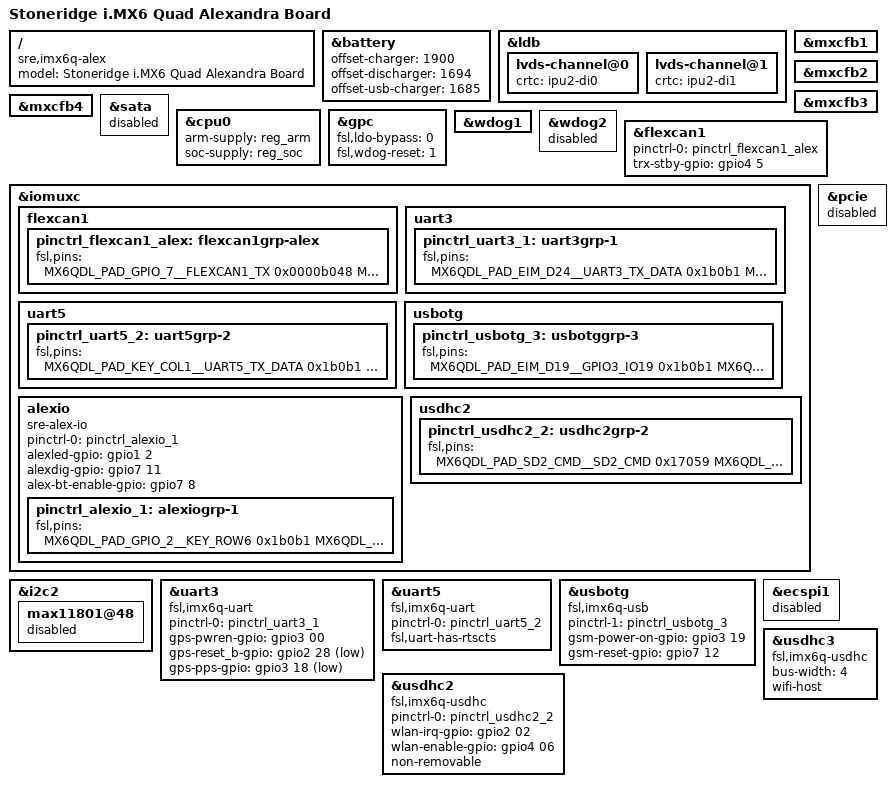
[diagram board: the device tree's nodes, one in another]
/*
 * Copyright 2012 Freescale Semiconductor, Inc.
 * Copyright 2011 Linaro Ltd.
 * Copyright (C) 2014 Stoneridge Electronics AB.
 *
 * The code contained herein is licensed under the GNU General Public
 * License. You may obtain a copy of the GNU General Public License
 * Version 2 or later at the following locations:
 *
 * http://www.opensource.org/licenses/gpl-license.html
 * http://www.gnu.org/copyleft/gpl.html
 */

/dts-v1/;

#include "imx6q.dtsi"
#include "imx6qdl-alex.dtsi"

/ {
	model = "Stoneridge i.MX6 Quad Alexandra Board";
	compatible = "sre,imx6q-alex", "fsl,imx6q";
};



&battery {
	offset-charger = <1900>;
	offset-discharger = <1694>;
	offset-usb-charger = <1685>;
};

&ldb {
	lvds-channel@0 {
		crtc = "ipu2-di0";
	};

	lvds-channel@1 {
		crtc = "ipu2-di1";
	};
};

&mxcfb1 {
	status = "okay";
};

&mxcfb2 {
	status = "okay";
};

&mxcfb3 {
	status = "okay";
};

&mxcfb4 {
	status = "okay";
};

&sata {
	status = "okay";
};

&cpu0 {
	arm-supply = <&reg_arm>;
	soc-supply = <&reg_soc>;
};

&gpc {
	/* use ldo-enable, u-boot will check it and configure */
	fsl,ldo-bypass = <0>;
	/* watchdog select of reset source */
	fsl,wdog-reset = <1>;
};

&wdog1 {
	status = "okay";
};

&wdog2 {
	status = "disabled";
};

&flexcan1 {
	pinctrl-names = "default";
	pinctrl-0 = <&pinctrl_flexcan1_alex>;
	trx-stby-gpio = <&gpio4 5 GPIO_ACTIVE_HIGH>;
	status = "okay";
};

&iomuxc {
	flexcan1 {
		pinctrl_flexcan1_alex: flexcan1grp-alex {
			fsl,pins = <
				MX6QDL_PAD_GPIO_7__FLEXCAN1_TX   0x0000b048
				MX6QDL_PAD_GPIO_8__FLEXCAN1_RX   0x0001b040
			>;
		};
	};
};

&sata {
	status = "disabled";
};

&i2c2 {
	max11801@48 {
		status = "disabled";
	};
};

&iomuxc {
	uart3 {
		pinctrl_uart3_1: uart3grp-1 {
			fsl,pins = <
				/* First value, see imx6q-pinfunc.h, which defines     */
				/* <mux_reg conf_reg input_reg mux_mode input_val>     */
				/* Second is Pad Control Register                      */
				/* Pad Control Register - iMX6 Ref Man p2188-2189,2228 */
				/* 2225,2176 */
				/* Values according to common FSL code setup           */
				/* Might need changing for other pull up/down, stregth etc */
				MX6QDL_PAD_EIM_D24__UART3_TX_DATA 0x1b0b1 /* UART3_TXD */
				MX6QDL_PAD_EIM_D25__UART3_RX_DATA 0x1b0b1 /* UART3_RXD */
				MX6QDL_PAD_EIM_DA0__GPIO3_IO00	0x1b0b1 /* GPS_PWREN */
				MX6QDL_PAD_EIM_EB0__GPIO2_IO28	0x1b0b1 /* GPS_RESET_B */
				MX6QDL_PAD_EIM_D18__GPIO3_IO18	0x1b0b1 /* GPS_PPS */
				>;
		};


	};
};

&uart3 {
	compatible = "fsl,imx6q-uart", "fsl,imx21-uart", "sre-alex-gps";
	pinctrl-names = "default";
	pinctrl-0 = <&pinctrl_uart3_1>;
	gps-pwren-gpio = <&gpio3 00 GPIO_ACTIVE_HIGH>;
	gps-reset_b-gpio = <&gpio2 28 GPIO_ACTIVE_LOW>;
	gps-pps-gpio = <&gpio3 18 GPIO_ACTIVE_LOW>;

	status = "okay";
};

/* Bluetooth UART*/
&iomuxc {
	uart5 {
		pinctrl_uart5_2: uart5grp-2 {
			fsl,pins = <
				MX6QDL_PAD_KEY_COL1__UART5_TX_DATA 0x1b0b1
				MX6QDL_PAD_KEY_ROW1__UART5_RX_DATA 0x1b0b1
				/* Collides with Flexcan 2: */
				MX6QDL_PAD_KEY_ROW4__UART5_CTS_B 0x1b0b1
				MX6QDL_PAD_KEY_COL4__UART5_RTS_B 0x1b0b1
				>;
		};
	};
};

&uart5 {
	compatible = "fsl,imx6q-uart", "fsl,imx21-uart";
	pinctrl-names = "default";
	pinctrl-0 = <&pinctrl_uart5_2>;
	fsl,uart-has-rtscts;
	status = "okay";
};

&pcie {
	status = "disabled";
};

&iomuxc {
	usbotg {
		pinctrl_usbotg_3: usbotggrp-3 {
			fsl,pins = <
				MX6QDL_PAD_EIM_D19__GPIO3_IO19 0x1b0b1 /* GSM Power On */
				MX6QDL_PAD_GPIO_17__GPIO7_IO12 0x1b0b1 /* GSM Reset */
			>;
		};
	};
};


&usbotg {
	compatible = "fsl,imx6q-usb", "fsl,imx27-usb", "sre-alex-gsm";
	pinctrl-names = "default";
	pinctrl-1 = <&pinctrl_usbotg_3>;
	gsm-power-on-gpio = <&gpio3 19 0>;
	gsm-reset-gpio = <&gpio7 12 0>;
	status = "okay";
};





&iomuxc {
	alexio:alexio {
		pinctrl_alexio_1: alexiogrp-1 {
			fsl,pins = <
				MX6QDL_PAD_GPIO_2__KEY_ROW6    0x1b0b1	/* White LED */
				MX6QDL_PAD_GPIO_16__GPIO7_IO11 0x1b0b1  /* DIG (#4 in power connector) */
				MX6QDL_PAD_SD3_RST__GPIO7_IO08 0x1b0b1  /* BT Enable */
				>;
		};
	};
};




&alexio {
	compatible = "sre-alex-io";
	pinctrl-names = "default";
	pinctrl-0 = <&pinctrl_alexio_1>;
	alexled-gpio = <&gpio1 2 0>;
	alexdig-gpio = <&gpio7 11 0>;
	alex-bt-enable-gpio = <&gpio7 8 0>;
	status = "okay";
};



// WLAN
// Disable SPI config from SABRE board
&ecspi1 {
	status = "disabled";
};


&iomuxc {
	usdhc2 {
		pinctrl_usdhc2_2: usdhc2grp-2 {
			fsl,pins = <
				MX6QDL_PAD_SD2_CMD__SD2_CMD    0x17059
				MX6QDL_PAD_SD2_CLK__SD2_CLK    0x10059
				MX6QDL_PAD_SD2_DAT0__SD2_DATA0 0x17059
				MX6QDL_PAD_SD2_DAT1__SD2_DATA1 0x17059
				MX6QDL_PAD_SD2_DAT2__SD2_DATA2 0x17059
				MX6QDL_PAD_SD2_DAT3__SD2_DATA3 0x17059
				MX6QDL_PAD_NANDF_D2__GPIO2_IO02 0x80000000    // WL IRQ
				MX6QDL_PAD_KEY_COL0__GPIO4_IO06 0x100b1    // WL EN
			>;
		};
	};
};



&usdhc2 {
	compatible = "fsl,imx6q-usdhc", "sre-alex-wlan";
	pinctrl-names = "default";
	pinctrl-0 = <&pinctrl_usdhc2_2>;
	wlan-irq-gpio = <&gpio2 02 0>;
	wlan-enable-gpio = <&gpio4 06 0>;
	non-removable;
	status = "okay";
};

&usdhc3 {
	compatible = "fsl,imx6q-usdhc", "sd8xxx-wlan";
	bus-width = <4>;
	wifi-host;
	status = "okay";
};
